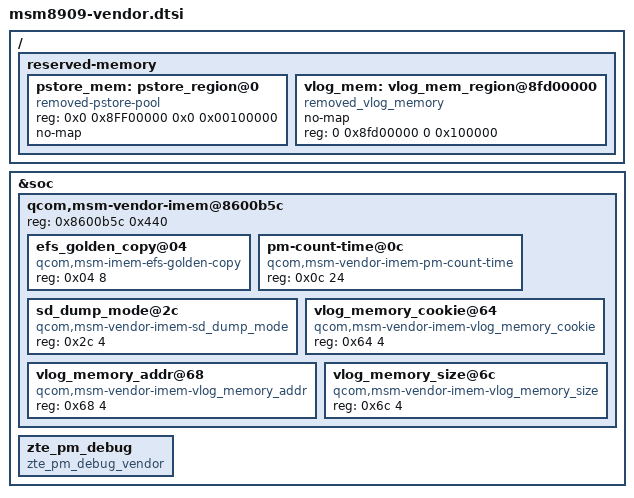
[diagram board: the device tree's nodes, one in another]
/* Copyright (c) 2014-2017, The Linux Foundation. All rights reserved.
 *
 * This program is free software; you can redistribute it and/or modify
 * it under the terms of the GNU General Public License version 2 and
 * only version 2 as published by the Free Software Foundation.
 *
 * This program is distributed in the hope that it will be useful,
 * but WITHOUT ANY WARRANTY; without even the implied warranty of
 * MERCHANTABILITY or FITNESS FOR A PARTICULAR PURPOSE.  See the
 * GNU General Public License for more details.
 */


/ {
	  reserved-memory {
		#address-cells = <2>;
		#size-cells = <2>;

		pstore_mem: pstore_region@0 {
			reg = <0x0 0x8FF00000 0x0 0x00100000>;
			compatible = "removed-pstore-pool";
			no-map;
		};

		vlog_mem:vlog_mem_region@8fd00000 {
			compatible = "removed_vlog_memory";
			no-map;
			reg = <0 0x8fd00000 0 0x100000>;
		};
	};
};


&soc {
	qcom,msm-vendor-imem@8600b5c {
		reg = <0x8600b5c 0x440>; /* Address and size of IMEM */
		ranges = <0x0 0x8600b5c 0x440>;
		#address-cells = <1>;
		#size-cells = <1>;
		efs_golden_copy@04 {
			compatible = "qcom,msm-imem-efs-golden-copy";
			reg = <0x04 8>;
		};
		pm-count-time@0c {
			compatible = "qcom,msm-vendor-imem-pm-count-time";
			reg = <0x0c 24>;
		};

		sd_dump_mode@2c {
			compatible = "qcom,msm-vendor-imem-sd_dump_mode";
			reg = <0x2c 4>;
		};

		vlog_memory_cookie@64 {
			compatible = "qcom,msm-vendor-imem-vlog_memory_cookie";
			reg = <0x64 4>;
		};

		vlog_memory_addr@68 {
			compatible = "qcom,msm-vendor-imem-vlog_memory_addr";
			reg = <0x68 4>;
		};

		vlog_memory_size@6c {
			compatible = "qcom,msm-vendor-imem-vlog_memory_size";
			reg = <0x6c 4>;
		};
	};

	zte_pm_debug {
		compatible = "zte_pm_debug_vendor";
	};
};
